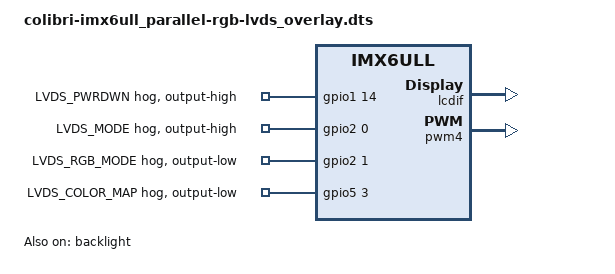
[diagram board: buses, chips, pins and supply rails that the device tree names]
// SPDX-License-Identifier: GPL-2.0-or-later OR MIT
/*
 * Copyright 2020-2021 Toradex
 */

// Enable the parallel RGB interface on the Colibri iMX6ULL and the LVDS
// trasceiver on the Iris v2.0A.

#include <dt-bindings/gpio/gpio.h>

/dts-v1/;
/plugin/;

/ {
	compatible = "toradex,colibri-imx6ull-emmc";
};

&backlight {
	status = "okay";
};

&can1 {
	// Disabled due to the SODIMM 55 and 63 pins overlapping
	status = "disabled";
};

&gpio1 {
	// This turns the LVDS transceiver on
	LVDS_PWRDWN {
		gpio-hog;
		gpios = <14 GPIO_ACTIVE_HIGH>; /* SODIMM 99 */
		line-name = "LVDS_PWRDWN";
		output-high;
	};
};

&gpio2 {
	// This switches the LVDS transceiver to the single-channel output mode
	LVDS_MODE {
		gpio-hog;
		gpios = <0 GPIO_ACTIVE_HIGH>; /* SODIMM 55 */
		line-name = "LVDS_MODE";
		output-high;
	};

	// This switches the LVDS transceiver to the 24-bit RGB mode
	LVDS_RGB_MODE {
		gpio-hog;
		gpios = <1 GPIO_ACTIVE_HIGH>; /* SODIMM 63 */
		line-name = "LVDS_RGB_MODE";
		output-low;
	};
};

&gpio5 {
	// This switches the LVDS transceiver to VESA color mapping mode
	LVDS_COLOR_MAP {
		gpio-hog;
		gpios = <3 GPIO_ACTIVE_HIGH>; /* SODIMM 95 */
		line-name = "LVDS_COLOR_MAP";
		output-low;
	};
};

&lcdif {
	status = "okay";
};

&panel_dpi {
	status = "okay";
};

&pwm4 {
	status = "okay";
};
